# STM32G0B1 register map
File version: 1.8
CPU: CM0 r0p1, little endian, MPU, no FPU, 4 interrupt priority bits
Registers are 32-bit, read-write, reset 0x0 unless marked. A register's access mark holds for its fields unless they carry their own. Offsets are from the block's base; [hi:lo] are bit positions; {n}, {i} and the like mark numbered series.

## SYSCFG — System configuration controller
Base 0x40010000
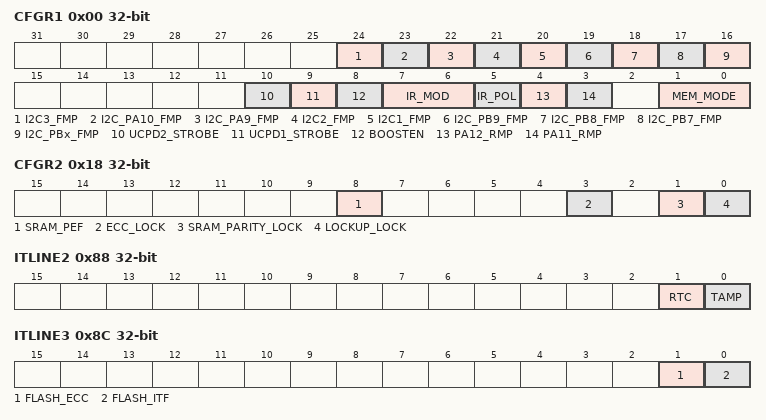
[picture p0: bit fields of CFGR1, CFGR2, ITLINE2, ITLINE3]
0x00 CFGR1 — SYSCFG configuration register 1
  [24] I2C3_FMP
  [23] I2C_PA10_FMP — Fast Mode Plus (FM+) driving capability activation bits
  [22] I2C_PA9_FMP — Fast Mode Plus (FM+) driving capability activation bits
  [21] I2C2_FMP — FM+ driving capability activation for I2C2
  [20] I2C1_FMP — FM+ driving capability activation for I2C1
  [19] I2C_PB9_FMP
  [18] I2C_PB8_FMP
  [17] I2C_PB7_FMP
  [16] I2C_PBx_FMP — Fast Mode Plus (FM+) driving capability activation bits
  [10] UCPD2_STROBE — Strobe signal bit for UCPD2
  [9] UCPD1_STROBE — Strobe signal bit for UCPD1
  [8] BOOSTEN — I/O analog switch voltage booster enable
  [7:6] IR_MOD — IR Modulation Envelope signal selection.
  [5] IR_POL — IR output polarity selection
  [4] PA12_RMP — PA11 and PA12 remapping bit.
  [3] PA11_RMP
  [1:0] MEM_MODE — Memory mapping selection bits
0x18 CFGR2 — SYSCFG configuration register 1
  [8] SRAM_PEF — SRAM parity error flag
  [3] ECC_LOCK — ECC error lock bit
  [1] SRAM_PARITY_LOCK — SRAM parity lock bit
  [0] LOCKUP_LOCK — Cortex-M0+ LOCKUP bit enable bit
0x80 ITLINE0 ro — interrupt line 0 status register
  [0] WWDG — Window watchdog interrupt pending flag
0x88 ITLINE2 ro — interrupt line 2 status register
  [1] RTC, [0] TAMP
0x8C ITLINE3 ro — interrupt line 3 status register
  [1] FLASH_ECC, [0] FLASH_ITF
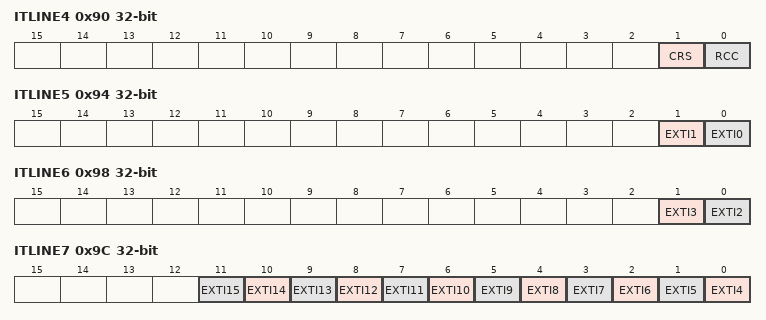
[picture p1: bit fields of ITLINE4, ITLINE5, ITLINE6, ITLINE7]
0x90 ITLINE4 ro — interrupt line 4 status register
  [1] CRS, [0] RCC
0x94 ITLINE5 ro — interrupt line 5 status register
  [1] EXTI1, [0] EXTI0
0x98 ITLINE6 ro — interrupt line 6 status register
  [1] EXTI3, [0] EXTI2
0x9C ITLINE7 ro — interrupt line 7 status register
  [n-4] EXTI{n} (n=4..15)
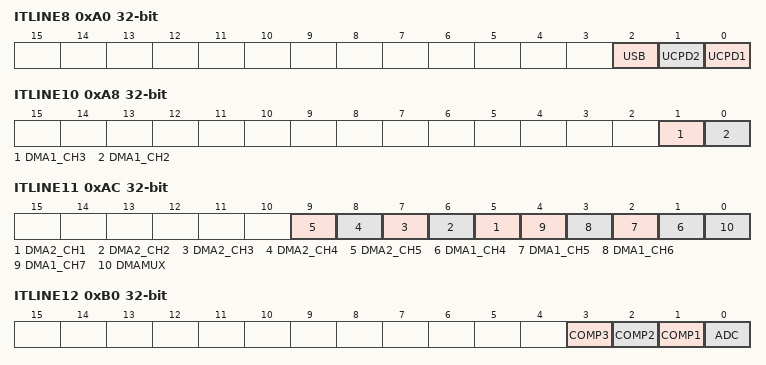
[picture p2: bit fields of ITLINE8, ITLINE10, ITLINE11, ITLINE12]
0xA0 ITLINE8 ro — interrupt line 8 status register
  [2] USB, [1] UCPD2, [0] UCPD1
0xA4 ITLINE9 ro — interrupt line 9 status register
  [0] DMA1_CH1
0xA8 ITLINE10 ro — interrupt line 10 status register
  [1] DMA1_CH3
  [0] DMA1_CH2 — DMA1_CH1
0xAC ITLINE11 ro — interrupt line 11 status register
  [n+4] DMA2_CH{n} (n=1..5), [n-3] DMA1_CH{n} (n=4..7), [0] DMAMUX
0xB0 ITLINE12 ro — interrupt line 12 status register
  [3] COMP3, [2] COMP2, [1] COMP1, [0] ADC
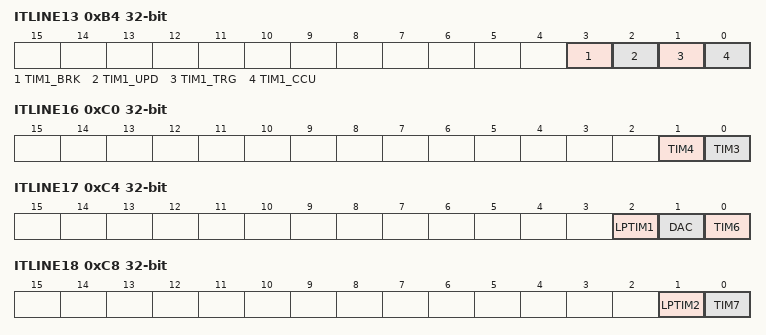
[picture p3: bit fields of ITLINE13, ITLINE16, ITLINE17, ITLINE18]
0xB4 ITLINE13 ro — interrupt line 13 status register
  [3] TIM1_BRK, [2] TIM1_UPD, [1] TIM1_TRG, [0] TIM1_CCU
0xB8 ITLINE14 ro — interrupt line 14 status register
  [0] TIM1_CC
0xBC ITLINE15 ro — interrupt line 15 status register
  [0] TIM2
0xC0 ITLINE16 ro — interrupt line 16 status register
  [1] TIM4, [0] TIM3
0xC4 ITLINE17 ro — interrupt line 17 status register
  [2] LPTIM1, [1] DAC, [0] TIM6
0xC8 ITLINE18 ro — interrupt line 18 status register
  [1] LPTIM2, [0] TIM7
0xCC ITLINE19 ro — interrupt line 19 status register
  [0] TIM14
0xD0 ITLINE20 ro — interrupt line 20 status register
  [0] TIM15
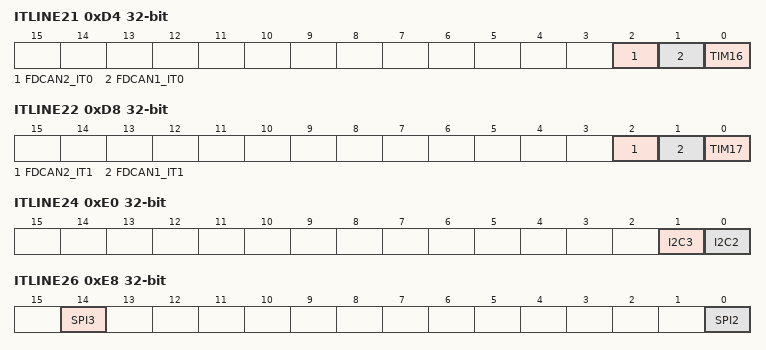
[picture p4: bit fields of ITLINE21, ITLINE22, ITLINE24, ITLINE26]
0xD4 ITLINE21 ro — interrupt line 21 status register
  [2] FDCAN2_IT0, [1] FDCAN1_IT0, [0] TIM16
0xD8 ITLINE22 ro — interrupt line 22 status register
  [2] FDCAN2_IT1, [1] FDCAN1_IT1, [0] TIM17
0xDC ITLINE23 ro — interrupt line 23 status register
  [0] I2C1
0xE0 ITLINE24 ro — interrupt line 24 status register
  [1] I2C3, [0] I2C2
0xE4 ITLINE25 ro — interrupt line 25 status register
  [0] SPI1
0xE8 ITLINE26 ro — interrupt line 26 status register
  [14] SPI3, [0] SPI2
0xEC ITLINE27 ro — interrupt line 27 status register
  [0] USART1
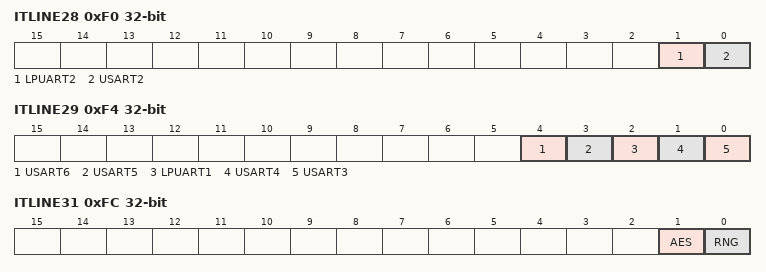
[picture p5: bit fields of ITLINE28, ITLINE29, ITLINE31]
0xF0 ITLINE28 ro — interrupt line 28 status register
  [1] LPUART2, [0] USART2
0xF4 ITLINE29 ro — interrupt line 29 status register
  [4] USART6, [3] USART5, [2] LPUART1, [1] USART4, [0] USART3
0xF8 ITLINE30 ro — interrupt line 25 status register
  [0] CEC
0xFC ITLINE31 ro — interrupt line 25 status register
  [1] AES, [0] RNG

## VREFBUF — System configuration controller
Base 0x40010030
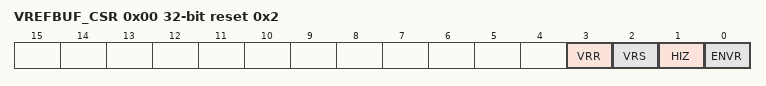
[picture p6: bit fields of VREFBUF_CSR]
0x00 VREFBUF_CSR access per field reset 0x2 — VREFBUF control and status register
  [3] VRR ro — Voltage reference buffer ready
    0=the voltage reference buffer output is not ready; 1=the voltage reference buffer output reached the requested level
  [2] VRS rw — Voltage reference scale This bit selects the value generated by the voltage reference buffer.
    0=Voltage reference set to VREF_OUT1 (around 2.048 V); 1=Voltage reference set to VREF_OUT2 (around 2.5 V)
  [1] HIZ rw — High impedance mode This bit controls the analog switch to connect or not the VREF+ pin. Refer to for the mode descriptions depending on ENVR bit configuration.
    0=VREF+ pin is internally connected to the voltage reference buffer output; 1=VREF+ pin is high impedance
  [0] ENVR rw — Voltage reference buffer mode enable This bit is used to enable the voltage reference buffer mode.
    0=Internal voltage reference mode disable (external voltage reference mode); 1=Internal voltage reference mode (reference buffer enable or hold mode) enable
0x04 VREFBUF_CCR — VREFBUF calibration control register
  [5:0] TRIM — Trimming code These bits are automatically initialized after reset with the trimming value stored in the Flash memory during the production test. Writing into these bits allows the tuning of the internal reference buffer voltage.

## WWDG — System window watchdog
Base 0x40002C00
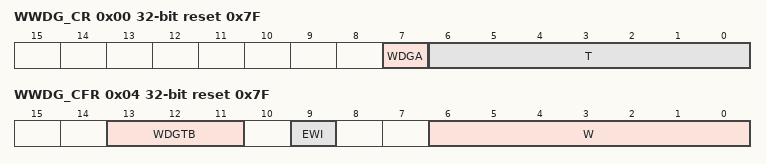
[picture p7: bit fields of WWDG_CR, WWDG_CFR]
0x00 WWDG_CR reset 0x7F — Control register
  [7] WDGA — Activation bit This bit is set by software and only cleared by hardware after a reset. When WDGA=1, the watchdog can generate a reset.
    0=Watchdog disabled; 1=Watchdog enabled
  [6:0] T — 7-bit counter (MSB to LSB) These bits contain the value of the watchdog counter, decremented every (4096 x 2WDGTB[1:0]) PCLK cycles. A reset is produced when it is decremented from 0x40 to 0x3F (T6 becomes cleared).
0x04 WWDG_CFR reset 0x7F — Configuration register
  [13:11] WDGTB — Timer base The timebase of the prescaler can be modified as follows:
    0=CK Counter Clock (PCLK div 4096) div 1; 1=CK Counter Clock (PCLK div 4096) div 2; 2=CK Counter Clock (PCLK div 4096) div 4; 3=CK Counter Clock (PCLK div 4096) div 8; 4=CK Counter Clock (PCLK div 4096) div 16; 5=CK Counter Clock (PCLK div 4096) div 32; 6=CK Counter Clock (PCLK div 4096) div 64; 7=CK Counter Clock (PCLK div 4096) div 128
  [9] EWI — Early wakeup interrupt When set, an interrupt occurs whenever the counter reaches the value 0x40. This interrupt is only cleared by hardware after a reset.
  [6:0] W — 7-bit window value These bits contain the window value to be compared with the down-counter.
0x08 WWDG_SR — Status register
  [0] EWIF — Early wakeup interrupt flag
